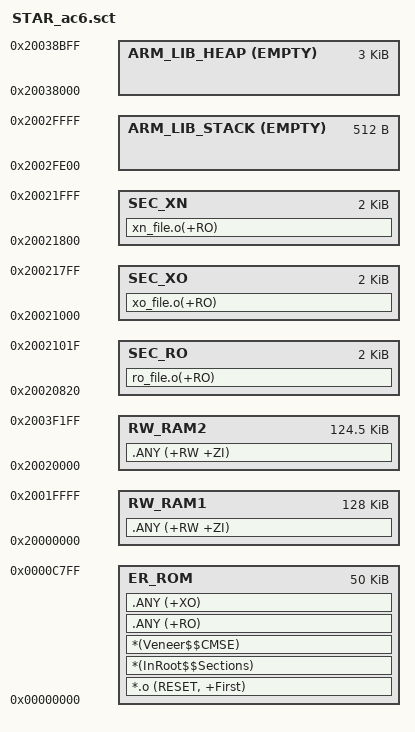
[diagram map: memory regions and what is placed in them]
#! armclang -E --target=arm-arm-none-eabi -mcpu=cortex-m33 -xc
; command above MUST be in first line (no comment above!)

/*
;-------- <<< Use Configuration Wizard in Context Menu >>> -------------------
*/

/*
* ROM,   0x00000000
* SCRAM, 0x00100000
* SRAM,  0x20000000
* NSRAM, 0x20100000
*/


/*--------------------- Flash Configuration ----------------------------------
; <h> Flash Configuration
;   <o0> Flash Base Address <0x0-0xFFFFFFFF:8>
;   <o1> Flash Size (in Bytes) <0x0-0xFFFFFFFF:8>
; </h>
 *----------------------------------------------------------------------------*/
#define __ROM_BASE     0x00000000
#define __ROM_SIZE     0x0000C800

/*--------------------- Embedded RAM Configuration ---------------------------
; <h> RAM Configuration
;   <o0> RAM Base Address    <0x0-0xFFFFFFFF:8>
;   <o1> RAM Size (in Bytes) <0x0-0xFFFFFFFF:8>
; </h>
 *----------------------------------------------------------------------------*/
#define __RAM_BASE     0x20000000
#define __RAM_SIZE     0x00040000

#define __RAM1_BASE     0x20000000
#define __RAM1_SIZE     (0x20020800 - 0x20000000)
#define __RAM2_BASE     (0x20021800 + 0x00000800)
#define __RAM2_SIZE     (0x20000000 + 0x00030000 - 0x20021800 - 0x00000800)

/*--------------------- Stack / Heap Configuration ---------------------------
; <h> Stack / Heap Configuration
;   <o0> Stack Size (in Bytes) <0x0-0xFFFFFFFF:8>
;   <o1> Heap Size (in Bytes) <0x0-0xFFFFFFFF:8>
; </h>
 *----------------------------------------------------------------------------*/
#define __STACK_SIZE       0x00000200
#define __HEAP_SIZE        0x00000C00


/*----------------------------------------------------------------------------
  User Stack & Heap boundary definition
 *----------------------------------------------------------------------------*/
#define __STACK_TOP        (0x20030000)      /* starts at end of RAM */
#define __HEAP_BASE        (0x20038000)             /* starts after RW_RAM section, 8 byte aligned */


/*----------------------------------------------------------------------------
  Scatter File Definitions definition
 *----------------------------------------------------------------------------*/
#define __RO_BASE         __ROM_BASE
#define __RO_SIZE         __ROM_SIZE

#define __RW_BASE         __RAM_BASE
#define __RW_SIZE        (__RAM_SIZE - __STACK_SIZE - __HEAP_SIZE)

#define __RW1_BASE         __RAM_BASE
#define __RW1_SIZE        (__RAM_SIZE - 0x00020000)

#define __RW2_BASE        (__RAM_BASE + 0x00020000)
#define __RW2_SIZE        (__RAM_SIZE - 0x00020000 - __STACK_SIZE - __HEAP_SIZE)

LR_ROM __RO_BASE __RO_SIZE  {                       ; load region size_region
  ER_ROM __RO_BASE __RO_SIZE  {                     ; load address = execution address
   *.o (RESET, +First)
   *(InRoot$$Sections)
   *(Veneer$$CMSE)                                  ; uncomment for secure applications
   .ANY (+RO)
   .ANY (+XO)
  }

  RW_RAM1 __RW1_BASE __RW1_SIZE  {                     ; RW data
   .ANY (+RW +ZI)
  }
  
  SEC_RO  0x20020820 0x800 {
	ro_file.o(+RO)
  }
  
  SEC_XO  0x20021000 0x800 {
	xo_file.o(+RO)
  }
  
  SEC_XN  0x20021800 0x800 {
	xn_file.o(+RO)
  }

  RW_RAM2 __RW2_BASE __RW2_SIZE  {                     ; RW data
   .ANY (+RW +ZI)
  }

#if __HEAP_SIZE > 0
  ARM_LIB_HEAP  __HEAP_BASE EMPTY  __HEAP_SIZE  {   ; Reserve empty region for heap
  }
#endif

  ARM_LIB_STACK __STACK_TOP EMPTY -__STACK_SIZE {   ; Reserve empty region for stack
  }
}
